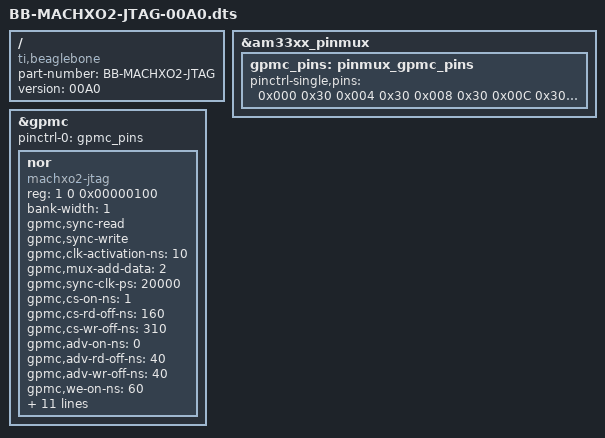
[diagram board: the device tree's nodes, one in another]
/dts-v1/;
/plugin/;

/ {
	compatible = "ti,beaglebone", "ti,beaglebone-black";

	/* identification */
	part-number = "BB-MACHXO2-JTAG";
	version = "00A0";

	#address-cells = <1>;
	#size-cells = <1>;

	fragment@0 {
		target = <&am33xx_pinmux>;
		__overlay__ {

			gpmc_pins: pinmux_gpmc_pins {
				pinctrl-single,pins = <
					0x000 0x30	/* gpmc_ad0 MODE0 | INPUT | PULLUP */
					0x004 0x30	/* gpmc_ad1 MODE0 | INPUT | PULLUP */
					0x008 0x30	/* gpmc_ad2 MODE0 | INPUT | PULLUP */
					0x00C 0x30	/* gpmc_ad3 MODE0 | INPUT | PULLUP */
					0x010 0x30	/* gpmc_ad4 MODE0 | INPUT | PULLUP */
					0x014 0x30	/* gpmc_ad5 MODE0 | INPUT | PULLUP */
					0x018 0x30	/* gpmc_ad6 MODE0 | INPUT | PULLUP */
					0x01C 0x30	/* gpmc_ad7 MODE0 | INPUT | PULLUP */
					0x080 0x08	/* gpmc_csn1 MODE0 | OUTPUT */
					0x08C 0x28	/* gpmc_clk MODE0 | INPUT */
					0x090 0x08	/* gpmc_advn_ale MODE0 | OUTPUT */
					0x094 0x08	/* gpmc_oen_ren MODE0 | OUTPUT */
					0x098 0x08	/* gpmc_wen MODE0 | OUTPUT */
				>;
			};
		};
	};

	fragment@1 {
		target = <&gpmc>;
		depth = <1>;	/* only create devices on depth 1 */

		#address-cells = <1>;
		#size-cells = <1>;
		ranges;

		__overlay__ {
			status = "okay";
			#address-cells = <2>;
			#size-cells = <1>;

			pinctrl-names = "default";
			pinctrl-0 = <&gpmc_pins>;

			/* chip select ranges */
			ranges = <0 0 0x08000000 0x10000000>,	/* bootloader has this enabled */
				 <1 0 0x18000000 0x08000000>,
				 <2 0 0x20000000 0x08000000>,
				 <3 0 0x28000000 0x08000000>,
				 <4 0 0x30000000 0x08000000>,
				 <5 0 0x38000000 0x04000000>,
				 <6 0 0x3c000000 0x04000000>;

			nor {
				compatible = "machxo2-jtag";
				status = "okay";

				reg = <1 0 0x00000100>;		/* CS1 */

				bank-width = <1>;		/* GPMC_CONFIG1_DEVICESIZE(1) */

				gpmc,sync-read;			/* GPMC_CONFIG1_READTYPE_SYNC */
				gpmc,sync-write;		/* GPMC_CONFIG1_WRITETYPE_SYNC */
				gpmc,clk-activation-ns = <10>;	/* GPMC_CONFIG1_CLKACTIVATIONTIME(1) */
				gpmc,mux-add-data = <2>;	/* GPMC_CONFIG1_MUXTYPE(2) */

				gpmc,sync-clk-ps = <20000>;	/* CONFIG2 */

				gpmc,cs-on-ns = <1>;
				gpmc,cs-rd-off-ns = <160>;
				gpmc,cs-wr-off-ns = <310>;

				gpmc,adv-on-ns = <0>;		/* CONFIG3 */
				gpmc,adv-rd-off-ns = <40>;
				gpmc,adv-wr-off-ns = <40>;

				gpmc,we-on-ns = <60>;		/* CONFIG4 */
				gpmc,we-off-ns = <310>;
				gpmc,oe-on-ns = <60>;
				gpmc,oe-off-ns = <160>;

				gpmc,access-ns = <140>;
				gpmc,rd-cycle-ns = <160>;
				gpmc,wr-cycle-ns = <310>;

				gpmc,wr-access-ns = <100>;		/* CONFIG 6 */
				gpmc,wr-data-mux-bus-ns = <60>;

				gpmc,bus-turnaround-ns = <40>;		/* CONFIG6:3:0 = 4 */
				gpmc,cycle2cycle-samecsen;		/* CONFIG6:7 = 1 */
				gpmc,cycle2cycle-delay-ns = <40>;	/* CONFIG6:11:8 = 4 */

			};

		};

	};
};
